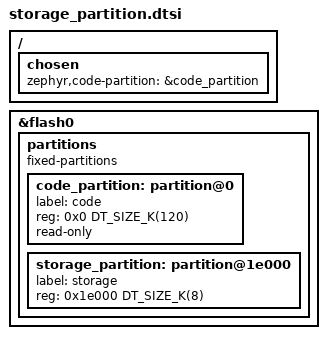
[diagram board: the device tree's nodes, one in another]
/ {
	chosen {
		zephyr,code-partition = &code_partition;
	};
};

&flash0 {
	partitions {
		compatible = "fixed-partitions";
		#address-cells = <1>;
		#size-cells = <1>;

		code_partition: partition@0 {
			label = "code";
			reg = <0x0 DT_SIZE_K(120)>;
			read-only;
		};

		storage_partition: partition@1e000 {
			label = "storage";
			reg = <0x1e000 DT_SIZE_K(8)>;
		};
	};
};
